VERSION ""

NS_ :

BS_:

BU_:

BU_: ExternalDevice EMUS_BMS
BU_: INV U2C VCU BMS

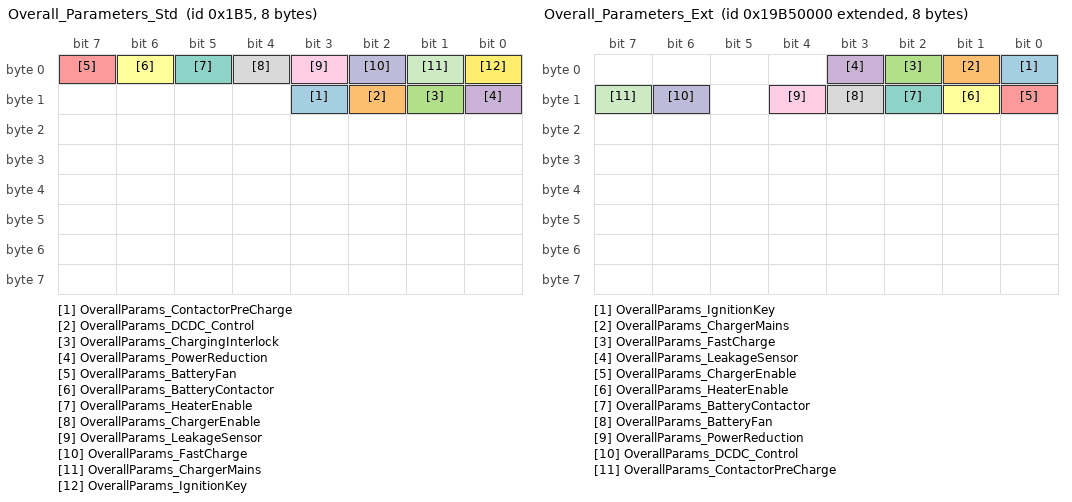
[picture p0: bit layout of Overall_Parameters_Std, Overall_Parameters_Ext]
BO_ 437 Overall_Parameters_Std: 8 EMUS_BMS
 SG_ OverallParams_ContactorPreCharge : 11|1@1+ (1,0) [0|1] "" Vector__XXX
 SG_ OverallParams_DCDC_Control : 10|1@1+ (1,0) [0|1] "" Vector__XXX
 SG_ OverallParams_ChargingInterlock : 9|1@1+ (1,0) [0|1] "" Vector__XXX
 SG_ OverallParams_PowerReduction : 8|1@1+ (1,0) [0|1] "" Vector__XXX
 SG_ OverallParams_BatteryFan : 7|1@1+ (1,0) [0|1] "" Vector__XXX
 SG_ OverallParams_BatteryContactor : 6|1@1+ (1,0) [0|1] "" Vector__XXX
 SG_ OverallParams_HeaterEnable : 5|1@1+ (1,0) [0|1] "" Vector__XXX
 SG_ OverallParams_ChargerEnable : 4|1@1+ (1,0) [0|1] "" Vector__XXX
 SG_ OverallParams_LeakageSensor : 3|1@1+ (1,0) [0|1] "" Vector__XXX
 SG_ OverallParams_FastCharge : 2|1@1+ (1,0) [0|1] "" Vector__XXX
 SG_ OverallParams_ChargerMains : 1|1@1+ (1,0) [0|1] "" Vector__XXX
 SG_ OverallParams_IgnitionKey : 0|1@1+ (1,0) [0|1] "" Vector__XXX

BO_ 2578776064 Overall_Parameters_Ext: 8 EMUS_BMS
 SG_ OverallParams_IgnitionKey : 0|1@1+ (1,0) [0|1] "" Vector__XXX
 SG_ OverallParams_ChargerMains : 1|1@1+ (1,0) [0|1] "" Vector__XXX
 SG_ OverallParams_FastCharge : 2|1@1+ (1,0) [0|1] "" Vector__XXX
 SG_ OverallParams_LeakageSensor : 3|1@1+ (1,0) [0|1] "" Vector__XXX
 SG_ OverallParams_ChargerEnable : 8|1@1+ (1,0) [0|1] "" Vector__XXX
 SG_ OverallParams_HeaterEnable : 9|1@1+ (1,0) [0|1] "" Vector__XXX
 SG_ OverallParams_BatteryContactor : 10|1@1+ (1,0) [0|1] "" Vector__XXX
 SG_ OverallParams_BatteryFan : 11|1@1+ (1,0) [0|1] "" Vector__XXX
 SG_ OverallParams_PowerReduction : 12|1@1+ (1,0) [0|1] "" Vector__XXX
 SG_ OverallParams_DCDC_Control : 14|1@1+ (1,0) [0|1] "" Vector__XXX
 SG_ OverallParams_ContactorPreCharge : 15|1@1+ (1,0) [0|1] "" Vector__XXX

BO_ 2578776071 Diagnostic_Codes_Ext: 8 EMUS_BMS
 SG_ DiagnosticCodes_UnderVoltage : 0|1@1+ (1,0) [0|1] "" Vector__XXX
 SG_ DiagnosticCodes_OverVoltage : 1|1@1+ (1,0) [0|1] "" Vector__XXX
 SG_ DiagnosticCodes_DchrgOvrCurrent : 2|1@1+ (1,0) [0|1] "" Vector__XXX
 SG_ DiagnosticCodes_ChrgOverCurrent : 3|1@1+ (1,0) [0|1] "" Vector__XXX
 SG_ DiagnosticCodes_CellModOverHeat : 4|1@1+ (1,0) [0|1] "" Vector__XXX
 SG_ DiagnosticCodes_Leakage : 5|1@1+ (1,0) [0|1] "" Vector__XXX
 SG_ DiagnosticCodes_NoCellComm : 6|1@1+ (1,0) [0|1] "" Vector__XXX
 SG_ DiagnosticCodes_LowVoltage : 8|1@1+ (1,0) [0|1] "" Vector__XXX
 SG_ DiagnosticCodes_HighCurrent : 9|1@1+ (1,0) [0|1] "" Vector__XXX
 SG_ DiagnosticCodes_HighCellModTemp : 10|1@1+ (1,0) [0|1] "" Vector__XXX
 SG_ DiagnosticCodes_CellOverHeat : 19|1@1+ (1,0) [0|1] "" Vector__XXX
 SG_ DiagnosticCodes_NoCurrentSensor : 20|1@1+ (1,0) [0|1] "" Vector__XXX
 SG_ DiagnosticCodes_PackUnderVoltage : 21|1@1+ (1,0) [0|1] "" Vector__XXX
 SG_ DiagnosticCodes_CellVoltValidity : 24|1@1+ (1,0) [0|1] "" Vector__XXX
 SG_ DiagnosticCodes_CellModTempValid : 25|1@1+ (1,0) [0|1] "" Vector__XXX
 SG_ DiagnosticCodes_CellBalancValid : 26|1@1+ (1,0) [0|1] "" Vector__XXX
 SG_ DiagnosticCodes_NumOfCellsValid : 27|1@1+ (1,0) [0|1] "" Vector__XXX
 SG_ DiagnosticCodes_BatChrgFinished : 28|1@1+ (1,0) [0|1] "" Vector__XXX
 SG_ DiagnosticCodes_CellTempValid : 29|1@1+ (1,0) [0|1] "" Vector__XXX
 SG_ DiagnosticCodes_MS_ConfError : 7|1@1+ (1,0) [0|1] "" Vector__XXX
 SG_ DiagnosticCodes_MSConfigMismatch : 11|1@1+ (1,0) [0|1] "" Vector__XXX
 SG_ DiagnosticCodes_MSComMalfunc : 12|1@1+ (1,0) [0|1] "" Vector__XXX
 SG_ DiagnosticCodes_HighCellTemp : 13|1@1+ (1,0) [0|1] "" Vector__XXX
 SG_ DiagnosticCodes_MSIntCANError : 16|1@1+ (1,0) [0|1] "" Vector__XXX
 SG_ DiagnosticCodes_MSCommCANFail : 17|1@1+ (1,0) [0|1] "" Vector__XXX
 SG_ DiagnosticCodes_ACPresnce : 18|1@1+ (1,0) [0|1] "" Vector__XXX

BO_ 444 Diagnostic_Codes_Std: 8 EMUS_BMS
 SG_ DiagnosticCodes_CellTempValid : 29|1@1+ (1,0) [0|1] "" Vector__XXX
 SG_ DiagnosticCodes_BatChrgFinished : 28|1@1+ (1,0) [0|1] "" Vector__XXX
 SG_ DiagnosticCodes_NumOfCellsValid : 27|1@1+ (1,0) [0|1] "" Vector__XXX
 SG_ DiagnosticCodes_CellBalancValid : 26|1@1+ (1,0) [0|1] "" Vector__XXX
 SG_ DiagnosticCodes_CellModTempValid : 25|1@1+ (1,0) [0|1] "" Vector__XXX
 SG_ DiagnosticCodes_CellVoltValidity : 24|1@1+ (1,0) [0|1] "" Vector__XXX
 SG_ DiagnosticCodes_PackUnderVoltage : 21|1@1+ (1,0) [0|1] "" Vector__XXX
 SG_ DiagnosticCodes_NoCurrentSensor : 20|1@1+ (1,0) [0|1] "" Vector__XXX
 SG_ DiagnosticCodes_CellOverHeat : 19|1@1+ (1,0) [0|1] "" Vector__XXX
 SG_ DiagnosticCodes_ACPresnce : 18|1@1+ (1,0) [0|1] "" Vector__XXX
 SG_ DiagnosticCodes_MSCommCANFail : 17|1@1+ (1,0) [0|1] "" Vector__XXX
 SG_ DiagnosticCodes_MSIntCANError : 16|1@1+ (1,0) [0|1] "" Vector__XXX
 SG_ DiagnosticCodes_HighCellTemp : 13|1@1+ (1,0) [0|1] "" Vector__XXX
 SG_ DiagnosticCodes_MSComMalfunc : 12|1@1+ (1,0) [0|1] "" Vector__XXX
 SG_ DiagnosticCodes_MSConfigMismatch : 11|1@1+ (1,0) [0|1] "" Vector__XXX
 SG_ DiagnosticCodes_HighCellModTemp : 10|1@1+ (1,0) [0|1] "" Vector__XXX
 SG_ DiagnosticCodes_HighCurrent : 9|1@1+ (1,0) [0|1] "" Vector__XXX
 SG_ DiagnosticCodes_LowVoltage : 8|1@1+ (1,0) [0|1] "" Vector__XXX
 SG_ DiagnosticCodes_MS_ConfError : 7|1@1+ (1,0) [0|1] "" Vector__XXX
 SG_ DiagnosticCodes_NoCellComm : 6|1@1+ (1,0) [0|1] "" Vector__XXX
 SG_ DiagnosticCodes_Leakage : 5|1@1+ (1,0) [0|1] "" Vector__XXX
 SG_ DiagnosticCodes_CellModOverHeat : 4|1@1+ (1,0) [0|1] "" Vector__XXX
 SG_ DiagnosticCodes_ChrgOverCurrent : 3|1@1+ (1,0) [0|1] "" Vector__XXX
 SG_ DiagnosticCodes_DchrgOvrCurrent : 2|1@1+ (1,0) [0|1] "" Vector__XXX
 SG_ DiagnosticCodes_OverVoltage : 1|1@1+ (1,0) [0|1] "" Vector__XXX
 SG_ DiagnosticCodes_UnderVoltage : 0|1@1+ (1,0) [0|1] "" Vector__XXX

BO_ 171 BMS_POST_Faults: 8 Vector__XXX
	SG_ Hardware_Gate_Desaturation_Fault : 0|1@1+ (1,0) [0|1] "" Vector__XXX
	SG_ HW_Over_current_Fault : 1|1@1+ (1,0) [0|1] "" Vector__XXX
	SG_ Accelerator_Shorted : 2|1@1+ (1,0) [0|1] "" Vector__XXX
	SG_ Accelerator_Open : 3|1@1+ (1,0) [0|1] "" Vector__XXX
	SG_ Current_Sensor_Low : 4|1@1+ (1,0) [0|1] "" Vector__XXX
	SG_ Current_Sensor_High : 5|1@1+ (1,0) [0|1] "" Vector__XXX
	SG_ Module_Temperature_Low : 6|1@1+ (1,0) [0|1] "" Vector__XXX
	SG_ Module_Temperature_High : 7|1@1+ (1,0) [0|1] "" Vector__XXX
	SG_ Control_PCB_Temperature_Low : 8|1@1+ (1,0) [0|1] "" Vector__XXX
	SG_ Control_PCB_Temperature_High : 9|1@1+ (1,0) [0|1] "" Vector__XXX
	SG_ Gate_Drive_PCB_Temperature_Low : 10|1@1+ (1,0) [0|1] "" Vector__XXX
	SG_ Gate_Drive_PCB_Temperature_High : 11|1@1+ (1,0) [0|1] "" Vector__XXX
	SG_ _5V_Sense_Voltage_Low : 12|1@1+ (1,0) [0|1] "" Vector__XXX
	SG_ _5V_Sense_Voltage_High : 13|1@1+ (1,0) [0|1] "" Vector__XXX
	SG_ _12V_Sense_Voltage_Low : 14|1@1+ (1,0) [0|1] "" Vector__XXX
	SG_ _12V_Sense_Voltage_High : 15|1@1+ (1,0) [0|1] "" Vector__XXX
	SG_ _2pt5V_Sense_Voltage_Low : 16|1@1+ (1,0) [0|1] "" Vector__XXX
	SG_ _2pt5V_Sense_Voltage_High : 17|1@1+ (1,0) [0|1] "" Vector__XXX
	SG_ _1pt5V_Sense_Voltage_Low : 18|1@1+ (1,0) [0|1] "" Vector__XXX
	SG_ _1pt5V_Sense_Voltage_High : 19|1@1+ (1,0) [0|1] "" Vector__XXX
	SG_ DC_Bust_Voltage_High : 20|1@1+ (1,0) [0|1] "" Vector__XXX
	SG_ DC_Bus_Voltage_Low : 21|1@1+ (1,0) [0|1] "" Vector__XXX
	SG_ Pre_charge_Timeout : 22|1@1+ (1,0) [0|1] "" Vector__XXX
	SG_ Pre_charge_Voltage_Failure : 23|1@1+ (1,0) [0|1] "" Vector__XXX
	SG_ EEPROM_Checksum_Invalid : 24|1@1+ (1,0) [0|1] "" Vector__XXX
	SG_ EEPROM_Date_Out_of_Range : 25|1@1+ (1,0) [0|1] "" Vector__XXX
	SG_ EEPROM_Update_Required : 26|1@1+ (1,0) [0|1] "" Vector__XXX
	SG_ Hardware_DC_Bus_Over_Voltage_dur : 27|1@1+ (1,0) [0|1] "" Vector__XXX
	SG_ Gate_Driver_Initialization : 28|1@1+ (1,0) [0|1] "" Vector__XXX
	SG_ Reserved : 29|1@1+ (1,0) [0|1] "" Vector__XXX
	SG_ Brake_Shorten : 30|1@1+ (1,0) [0|1] "" Vector__XXX
	SG_ Brake_Open : 31|1@1+ (1,0) [0|1] "" Vector__XXX
	SG_ Motor_Over_speed_Fault : 32|1@1+ (1,0) [0|1] "" Vector__XXX
	SG_ Over_current_Fault : 33|1@1+ (1,0) [0|1] "" Vector__XXX
	SG_ Inverter_Over_temperature_Fault : 34|1@1+ (1,0) [0|1] "" Vector__XXX
	SG_ Accelerator_Input_Shorted_Fault : 35|1@1+ (1,0) [0|1] "" Vector__XXX
	SG_ Accelerator_Input_Open_Fault : 36|1@1+ (1,0) [0|1] "" Vector__XXX
	SG_ Direction_Command_Fault : 37|1@1+ (1,0) [0|1] "" Vector__XXX
	SG_ Inverter_Response_Time_out_Fault : 38|1@1+ (1,0) [0|1] "" Vector__XXX
	SG_ Hardware_Gate_Desaturation_2 : 39|1@1+ (1,0) [0|1] "" Vector__XXX
	SG_ Hardware_Over_current_Fault : 40|1@1+ (1,0) [0|1] "" Vector__XXX
	SG_ Under_voltage_Fault : 41|1@1+ (1,0) [0|1] "" Vector__XXX
	SG_ CAN_Command_Message_Lost_Fault : 42|1@1+ (1,0) [0|1] "" Vector__XXX
	SG_ Motor_Over_temperature_Fault : 43|1@1+ (1,0) [0|1] "" Vector__XXX
	SG_ Brake_Input_Shorted_Fault : 47|1@1+ (1,0) [0|1] "" Vector__XXX
	SG_ Brake_Input_Open_Fault : 48|1@1+ (1,0) [0|1] "" Vector__XXX
	SG_ Module_A_Over_temperature_Fault : 49|1@1+ (1,0) [0|1] "" Vector__XXX
	SG_ Module_B_Over_temperature_Fault : 50|1@1+ (1,0) [0|1] "" Vector__XXX
	SG_ Module_C_Over_temperature_Fault : 51|1@1+ (1,0) [0|1] "" Vector__XXX
	SG_ PCB_Over_temperature_Fault : 52|1@1+ (1,0) [0|1] "" Vector__XXX
	SG_ Gate_Drive_Board_1_Over_temp_Flt : 53|1@1+ (1,0) [0|1] "" Vector__XXX
	SG_ Gate_Drive_Board_2_Over_temp_Flt : 54|1@1+ (1,0) [0|1] "" Vector__XXX
	SG_ Gate_Drive_Board_3_Over_temp_Flt : 55|1@1+ (1,0) [0|1] "" Vector__XXX
	SG_ Current_Sensor_Fault : 56|1@1+ (1,0) [0|1] "" Vector__XXX
	SG_ Gate_Driver_Over_Voltage : 57|1@1+ (1,0) [0|1] "" Vector__XXX
	SG_ Hardware_DC_Bus_Over_voltage_Flt : 60|1@1+ (1,0) [0|1] "" Vector__XXX
	SG_ Resolver_Not_Connected : 62|1@1+ (1,0) [0|1] "" Vector__XXX

CM_ SG_ 2147483819 Hardware_Gate_Desaturation_Fault "Wheel-Based Vehicle Speed: Speed of the vehicle as calculated from wheel or tailshaft speed.";
BA_DEF_ SG_  "SPN" INT 0 524287;
BA_DEF_ BO_  "VFrameFormat" ENUM  "StandardCAN","ExtendedCAN","reserved","J1939PG";
BA_DEF_  "DatabaseVersion" STRING ;
BA_DEF_  "BusType" STRING ;
BA_DEF_  "ProtocolType" STRING ;
BA_DEF_  "DatabaseCompiler" STRING ;
BA_DEF_DEF_  "SPN" 0;
BA_DEF_DEF_  "VFrameFormat" "J1939PG";
BA_DEF_DEF_  "DatabaseVersion" "DEMO PLUS";
BA_DEF_DEF_  "BusType" "";
BA_DEF_DEF_  "ProtocolType" "";
BA_DEF_DEF_  "DatabaseCompiler" "";
BA_ "ProtocolType" "J1939";
BA_ "DatabaseCompiler" "CSS ELECTRONICS (WWW.CSSELECTRONICS.COM)";
BA_ "DatabaseVersion" "1.0.0";
BA_ "SPN" SG_ 2566844926 WheelBasedVehicleSpeed 84;

CM_ BU_ INV "The Cascadia Motion inverter";
CM_ BU_ U2C "Delphi DC/DC Converter";
CM_ BU_ VCU "The system vehicle control unit";
CM_ BU_ BMS "BMS Master";
CM_ SG_ 173 D4_Iq_Command "The commanded Q-axis current";
CM_ SG_ 173 D3_Id_Command "The commanded D-axis current";
CM_ SG_ 173 D2_Flux_Weakening_Output "This is the current output of the flux regulator.";
CM_ SG_ 173 D1_Modulation_Index "This is the modulation index. The scale factor is x100. To get the actual modulation index divide the value by 100.";
CM_ SG_ 172 D3_Power_On_Timer "Updated every 3 msec. This will roll over in approximately 150 days!";
CM_ SG_ 172 D2_Torque_Feedback "Estimated motor torque feedback";
CM_ SG_ 172 D1_Commanded_Torque "The commanded Torque";
CM_ BO_ 194 "The inverter response to each Parameter message that is received.";
CM_ SG_ 194 D2_Write_Success "0=Write failure, 1=Success";
CM_ SG_ 194 D3_Data_Response "All EEPROM data is 16 bits and is contained in bytes 4 and 5. Bytes 6 and 7 should be ignored.";
CM_ SG_ 194 D1_Parameter_Address_Response "Valid EEPROM Parameter CAN addresses are between 100 and 499.";
CM_ BO_ 193 "Parameter Message sent as needed by VCU to request info, change EEPROM, or command a function.";
CM_ SG_ 193 D3_Data_Command "All EEPROM data is 16 bits and is contained in bytes 4 and 5.";
CM_ SG_ 193 D2_Read_Write_Command "0=Read, 1=Write";
CM_ SG_ 193 D1_Parameter_Address_Command "Valid EEPROM Parameter CAN addresses are between 100 and 499.";
CM_ BO_ 192 "The command message is used to transmit data to the controller. This message is sent from a user supplied external controller to the PMxxx controller.";
CM_ SG_ 192 Inverter_Enable "0=Inverter OFF, 1 = Inverter ON";
CM_ SG_ 192 Direction_Command "0=CW, 1=CCW as veiwed from the shaft end of the motor";
CM_ SG_ 192 Speed_Command "Speed commandused when in speed mode";
CM_ SG_ 192 Torque_Command "Torque command when in torque mode";
CM_ SG_ 192 Inverter_Discharge "0=Discharge Disable,
=Discharge Enable";
CM_ SG_ 192 Torque_Limit_Command "Torque Limit, set to 0 to keep default";
CM_ SG_ 192 Speed_Mode_Enable "0 = No change to mode, 1 = change to speed mode from torque mode";
CM_ SG_ 192 RollingCounter "Rolling Counter command";
CM_ SG_ 171 D4_Run_Fault_Hi "Each bit represents a fault. Please refer to PM100 Users Manual for details.";
CM_ SG_ 171 D2_Post_Fault_Hi "Each bit represents a fault. Please refer to PM100 Users Manual for details.";
CM_ SG_ 171 D3_Run_Fault_Lo "Each bit represents a fault. Please refer to PM100 Users Manual for details.";
CM_ SG_ 171 D1_Post_Fault_Lo "Each bit represents a fault. Please refer to PM100 Users Manual for details.";
CM_ SG_ 170 D7_Direction_Command "1 = Forward
0 = 'Reverse' if inverter enabled  & 'Stopped' if inverter is disabled";
CM_ SG_ 170 D6_Inverter_Enable_State "0=Inverter Disabled, 
1=Inverter Enabled";
CM_ SG_ 170 D3_Relay_3_Status "0=OFF, 1=ON";
CM_ SG_ 170 D3_Relay_4_Status "0=OFF, 1=ON";
CM_ SG_ 170 D3_Relay_2_Status "0=OFF, 1=ON";
CM_ SG_ 170 D4_Inverter_Run_Mode "0=Torque Mode, 1=Speed Mode";
CM_ SG_ 170 D5_Inverter_Command_Mode "0=CAN mode, 1=VSM mode";
CM_ SG_ 170 D3_Relay_1_Status "0=OFF, 1=ON";
CM_ SG_ 170 D2_Inverter_State "Different states for the inverter state machine";
CM_ SG_ 170 D1_VSM_State "Different states for the vehicle state machine";
CM_ SG_ 170 D6_Inverter_Enable_Lockout "0=Lockout Disabled, 1=Lockout Enabled";
CM_ SG_ 170 D4_Inverter_Discharge_State "0 = Disabled, 1 = Enabled, 2 = Speed Check, 3 = Active, 4 = Complete";
CM_ SG_ 170 D3_Relay_5_Status "0=OFF, 1=ON";
CM_ SG_ 170 D3_Relay_6_Status "0=OFF, 1=ON";
CM_ SG_ 170 D7_BMS_Active "0 = BMS Not Active, 1 = BMS Active";
CM_ SG_ 170 D7_BMS_Torque_Limiting "0 = Not Limiting, 1 = Limiting";
CM_ SG_ 170 D7_Max_Speed_Limiting "0 = Not Limiting, 1 = torque limiting due to maximum speed";
CM_ SG_ 170 D7_Low_Speed_Limiting "0 = Not Limiting, 1 = Current limiting due to low motor speed";
CM_ SG_ 170 D5_Rolling_Counter "The current rolling counter value.";
CM_ SG_ 170 D1_PWM_Frequency "The inverter PWM frequency";
CM_ SG_ 170 D6_Start_Mode_Active "If in Key Switch Mode 1 then indicates status of Start input being applied.  0 = not active, 1 = active";
CM_ SG_ 169 D4_Reference_Voltage_12_0 "12V Input Voltage";
CM_ SG_ 169 D3_Reference_Voltage_5_0 "Transducer voltage";
CM_ SG_ 169 D2_Reference_Voltage_2_5 "Internal reference voltage";
CM_ SG_ 169 D1_Reference_Voltage_1_5 "Internal reference voltage";
CM_ SG_ 168 D4_Iq "The measured Iq current";
CM_ SG_ 168 D3_Id "The measured Id current";
CM_ SG_ 168 D2_Flux_Feedback "The estimated flux";
CM_ SG_ 168 D1_Flux_Command "The commanded flux";
CM_ SG_ 167 D4_VBC_Vq_Voltage "Measured value of the voltage between Phase B and Phase C";
CM_ SG_ 167 D3_VAB_Vd_Voltage "Measured value of the voltage betwen phase A and Phase B";
CM_ SG_ 167 D2_Output_Voltage "The calculated value of the output voltage, in peak line-neutral volts";
CM_ SG_ 167 D1_DC_Bus_Voltage "The actual measured value of the DC bus voltage";
CM_ SG_ 166 D4_DC_Bus_Current "The Calculated DC Bus Current";
CM_ SG_ 166 D3_Phase_C_Current "The measured value of Phase C current";
CM_ SG_ 166 D2_Phase_B_Current "The measured value of Phase B current";
CM_ SG_ 166 D1_Phase_A_Current "The measured value of Phase A current";
CM_ SG_ 165 D4_Delta_Resolver_Filtered "Used in calibration of resolver angle adjustment.";
CM_ SG_ 165 D3_Electrical_Output_Frequency "The actual electrical frequency of the inverter";
CM_ SG_ 165 D2_Motor_Speed "The measured speed of the motor";
CM_ SG_ 165 D1_Motor_Angle_Electrical "The Electrical Angle of the motor as read by the encoder or resolver";
CM_ SG_ 164 D5_Digital_Input_5 "Status of Digital Input #5";
CM_ SG_ 164 D4_Digital_Input_4 "Status of Digital Input #4";
CM_ SG_ 164 D3_Digital_Input_3 "Status of Digital Input #3";
CM_ SG_ 164 D2_Digital_Input_2 "Status of Digital Input #2";
CM_ SG_ 164 D1_Digital_Input_1 "Status of Digital Input #1";
CM_ SG_ 164 D6_Digital_Input_6 "Status of Digital Input #6";
CM_ SG_ 164 D7_Digital_Input_7 "Status of Digital Input #7";
CM_ SG_ 164 D8_Digital_Input_8 "Status of Digital Input #8";
CM_ SG_ 163 D4_Analog_Input_4 "Voltage on Analog Input #4";
CM_ SG_ 163 D3_Analog_Input_3 "Voltage on Analog Input #3";
CM_ SG_ 163 D2_Analog_Input_2 "Voltage on Analog Input #2";
CM_ SG_ 163 D1_Analog_Input_1 "Voltage on Analog Input #1";
CM_ SG_ 163 D5_Analog_Input_5 "Voltage on Analog Input #5";
CM_ SG_ 163 D6_Analog_Input_6 "Voltage on Analog Input #6";
CM_ SG_ 162 D4_Torque_Shudder "Shudder compensation value of torque";
CM_ SG_ 162 D3_Motor_Temperature "Motor Temperature Sensor";
CM_ SG_ 162 D2_RTD5_Temperature "RTD 5 (PT1000) Temperature (Gen 2 only)";
CM_ SG_ 162 D1_RTD4_Temperature "RTD 4 (PT1000) Temperature (Gen 2 only)";
CM_ SG_ 161 D4_RTD3_Temperature "RTD input 3 (PT1000) Temperature (Gen 2 only)";
CM_ SG_ 161 D3_RTD2_Temperature "RTD input 2 (PT1000) Temperature";
CM_ SG_ 161 D2_RTD1_Temperature "RTD input 1 (PT1000) Temperature";
CM_ SG_ 161 D1_Control_Board_Temperature "Control Board Temperature";
CM_ SG_ 160 D4_Gate_Driver_Board "Gate Driver Board Temperature";
CM_ SG_ 160 D3_Module_C "IGBT Module C Temperature";
CM_ SG_ 160 D2_Module_B "IGBT Module B Temperature";
CM_ SG_ 160 D1_Module_A "IGBT Module A Temperature";
CM_ BO_ 471 "Enable message sent to Delphi DC/DC converter.";
CM_ BO_ 469 "Response from Delphi DC/DC converter.";
CM_ BO_ 514 "Message sent by BMS for inverter DC current limiting.";
CM_ SG_ 514 D1_Max_Discharge_Current "Maximum discharge current from BMS";
CM_ SG_ 514 D2_Max_Charge_Current "Maximum charge current from BMS";
CM_ BO_ 176 "To enable fast message set CAN ACTIVE MSGS HI WORD to 0xFFFE.  Setting to default value of 0xFFFF will disable the fast message.";
CM_ SG_ 176 Fast_Torque_Command "The commanded torque";
CM_ SG_ 176 Fast_Torque_Feedback "The estimated torque";
CM_ SG_ 176 Fast_Motor_Speed "Motor speed";
CM_ SG_ 176 Fast_DC_Bus_Voltage "DC Bus Voltage";
BA_DEF_ BO_  "GenMsgCycleTime" INT 0 100000;
BA_DEF_  "BusType" STRING ;
BA_DEF_DEF_  "GenMsgCycleTime" 0;
BA_DEF_DEF_  "BusType" "CAN";
BA_ "GenMsgCycleTime" BO_ 172 10;
BA_ "GenMsgCycleTime" BO_ 192 5;
BA_ "GenMsgCycleTime" BO_ 171 100;
BA_ "GenMsgCycleTime" BO_ 170 100;
BA_ "GenMsgCycleTime" BO_ 169 100;
BA_ "GenMsgCycleTime" BO_ 168 10;
BA_ "GenMsgCycleTime" BO_ 167 10;
BA_ "GenMsgCycleTime" BO_ 166 10;
BA_ "GenMsgCycleTime" BO_ 165 10;
BA_ "GenMsgCycleTime" BO_ 164 10;
BA_ "GenMsgCycleTime" BO_ 163 10;
BA_ "GenMsgCycleTime" BO_ 162 100;
BA_ "GenMsgCycleTime" BO_ 161 100;
BA_ "GenMsgCycleTime" BO_ 160 100;
BA_ "GenMsgCycleTime" BO_ 176 3;
VAL_ 192 Inverter_Enable 0 "Turn the inverter OFF" 1 "Turn the Inverter ON" ;
VAL_ 192 Direction_Command 0 "CW" 1 "CCW" ;
VAL_ 192 Inverter_Discharge 0 "Discharge Disable" 1 "Discharge Enable (if EEPROM parameter is set)" ;
VAL_ 170 D2_Inverter_State 0 "Power up" 1 "Stop" 2 "Open Loop" 3 "Closed Loop" 4 "Internal State" 5 "Internal State" 6 "Internal State" 7 "Internal State" 8 "Idle Run" 9 "Idle Stop" 10 "Internal State" 11 "Intern State" 12 "Internal State" ;
VAL_ 170 D1_VSM_State 0 "VSM Start State" 1 "Pre-Charge Init state" 2 "pre-charge active state" 3 "pre-charge complete state" 4 "VSM wait state" 5 "VSM ready state" 6 "Motor Running State" 7 "blink fault code state" 14 "Shutdown state for Key Switch Mode 1" 15 "Reset the inverter" ;

CM_ BO_ 2578776070 "Energy Parameters Extended";
CM_ BO_ 2578776069 "State Of Charge Parameters Extended";
CM_ BO_ 2578776065 "Battery Voltage Overall Parameters Extended";
CM_ BO_ 2578776064 "Overall Parameters Extended";
CM_ BO_ 2578776071 "Diagnostic Codes Extended";
CM_ SG_ 2578776071 DiagnosticCodes_MSComMalfunc "DiagnosticCodes Master Slave Communication Malfunction";
CM_ BO_ 2578776066 "Cell Module Temperature Overall Parameters Extended";
CM_ BO_ 2578776072 "Cell Temperature Overall Parameters Extended";
CM_ BO_ 2578776067 "Cell Balancing Overall Parameters Extended";
CM_ BO_ 2578777088 "Configuration Parameters Extended";
CM_ BO_ 2578777090 "Login Request Response Extended";
CM_ BO_ 2578777089 "Contactor Control Extended";
CM_ BO_ 2578777600 "Energy Parameters Extended";
CM_ BO_ 2578777344 "State Of Charge Parameters Extended";
CM_ BO_ 2578777092 "Statistics Extended";
CM_ BO_ 2578777093 "Events Extended";
CM_ BO_ 2578776320 "Individual Cells Voltages Extended Option A";
CM_ BO_ 2578776576 "Individual Cell Module Temperatures Extended Option A";
CM_ BO_ 2578778112 "Individual Cell Temperatures Extended Option A";
CM_ BO_ 450 "Individual Cell Balancing Rates Standard Option B";
CM_ SG_ 450 Individual_Cells_Group_Opt_B "Individual Cells Group Value for CAN Option B";
CM_ BO_ 437 "Overall Parameters Standard";
CM_ BO_ 444 "Diagnostic Codes Standard";
CM_ SG_ 444 DiagnosticCodes_MSComMalfunc "DiagnosticCodes Master Slave Communication Malfunction";
CM_ BO_ 438 "Battery Voltage Overall Parameters Standard";
CM_ BO_ 439 "Cell Module Overall Parameters Standard";
CM_ BO_ 445 "Cell Temperature Overall Params Standard";
CM_ BO_ 440 "Cell Bancing Rate Overall Params Standard";
CM_ BO_ 469 "Individual Cells Voltages Standard Option A";
CM_ BO_ 501 "Individual Cell Module Temperature Standard Option A";
CM_ BO_ 693 "Individual Cell Temperatures Standard Option A";
CM_ BO_ 533 "Individual Cell Balancing Rates Standard Option A";
CM_ BO_ 566 "Contactor Control Standard";
CM_ BO_ 443 "Energy Parameters Standard";
CM_ BO_ 442 "State Of Charge Parameters Standard";
CM_ BO_ 569 "Statistics Standard";
CM_ BO_ 2578776075 "Individual Cells Voltages Extended Option B";
CM_ SG_ 2578776075 Individual_Cells_Group_Opt_B "Individual Cells Group Value for CAN Option B";
CM_ BO_ 448 "Individual Cells Voltages Standard Option B";
CM_ SG_ 448 Individual_Cells_Group_Opt_B "Individual Cells Group Value for CAN Option B";
CM_ BO_ 2578776077 "Individual Cell Balancing Rate Extended Option B";
CM_ SG_ 2578776077 Individual_Cells_Group_Opt_B "Individual Cells Group Value for CAN Option B";
CM_ BO_ 2578776832 "Individual Cell Balancing Rate Extended Option A";
CM_ BO_ 2578776076 "Individual Cell Modules Temperature Extended Option B";
CM_ SG_ 2578776076 Individual_Cells_Group_Opt_B "Individual Cells Group Value for CAN Option B";
CM_ BO_ 449 "Individual Cell Module Temperature Standard Option B";
CM_ SG_ 449 Individual_Cells_Group_Opt_B "Individual Cells Group Value for CAN Option B";
CM_ BO_ 2578776078 "Individual Cell Temperatures Extended Option B";
CM_ SG_ 2578776078 Individual_Cells_Group_Opt_B "Individual Cells Group Value for CAN Option B";
CM_ BO_ 451 "Individual Cell Temperature Standard Option B";
CM_ SG_ 451 Individual_Cells_Group_Opt_B "Individual Cells Group Value for CAN Option B";
CM_ SG_ 1328 Neuro4_FirstByteFirstBit "Contactor State";
CM_ SG_ 1328 Neuro4_FirstByteSecondBit "if max cell voltage is less than fully charge minus balancing range, then allow regeneration";
BA_DEF_  "BusType" STRING ;
BA_DEF_DEF_  "BusType" "CAN";
VAL_ 2578776064 OverallParams_IgnitionKey 0 "OFF" 1 "ON" ;
VAL_ 2578776064 OverallParams_ChargerMains 0 "OFF" 1 "ON" ;
VAL_ 2578776064 OverallParams_FastCharge 0 "OFF" 1 "ON" ;
VAL_ 2578776064 OverallParams_LeakageSensor 0 "OFF" 1 "ON" ;
VAL_ 2578776064 OverallParams_ChargerEnable 0 "OFF" 1 "ON" ;
VAL_ 2578776064 OverallParams_HeaterEnable 0 "OFF" 1 "ON" ;
VAL_ 2578776064 OverallParams_BatteryContactor 0 "OFF" 1 "ON" ;
VAL_ 2578776064 OverallParams_BatteryFan 0 "OFF" 1 "ON" ;
VAL_ 2578776064 OverallParams_PowerReduction 0 "OFF" 1 "ON" ;
VAL_ 2578776064 OverallParams_DCDC_Control 0 "OFF" 1 "ON" ;
VAL_ 2578776064 OverallParams_ContactorPreCharge 0 "OFF" 1 "ON" ;
VAL_ 2578776064 OverallParams_ChargingStage 0 "OFF" 1 "ON" ;
VAL_ 2578776064 OverallParams_LastChargingError 0 "No Error" 1 "No Cell Communication" 2 "No Cell Communication 2" 3 "Maximum Charging Stage Duration Expired" 4 "Cell Communication Lost" 5 "Cannot Set Cell Module Balancing Threshold" 6 "Cell or Cell Module Temperature To High" 7 "Cell Commucation Lost 2" 8 "Number Of Cells Mismatch" 9 "Cell Over Voltage" 10 "Cell Protection Event Occurred" ;
VAL_ 2578776064 OverallParams_ChargingInterlock 0 "OFF" 1 "ON" ;
VAL_ 2578776064 OverallParams_ChrgStageDurat_LSB 0 "No Error" 1 "No Cell Communication" 2 "No Cell Communication 2" 3 "Maximum Charging Stage Duration Expired" 4 "Cell Communication Lost" 5 "Cannot Set Cell Module Balancing Threshold" 6 "Cell or Cell Module Temperature To High" 7 "Cell Commucation Lost 2" 8 "Number Of Cells Mismatch" 9 "Cell Over Voltage" 10 "Cell Protection Event Occurred" ;
VAL_ 2578777090 LoginLevel 0 "Guest" 1 "User" 2 "Admin" ;
VAL_ 2578777089 ContactorControl_ContactorState 0 "OPEN" 1 "CLOSE" ;
VAL_ 2578777092 Statistics_Identifier 0 "Total Disharge" 1 "Total Charge" 2 "Total Discharge Energy" 3 "Total Charge Energy" 4 "Total Discharge Time" 5 "Total Charge Time" 6 "Total Distance" 7 "Master Clear Count" 8 "Max Discharge Current" 9 "Max Charge Current" 10 "Min Cell Voltage" 11 "Max Cell Voltage" 12 "Max Cell Voltage Difference" 13 "Min Pack Voltage" 14 "Max Pack Voltage" 15 "Min Cell Module Temperature" 16 "Max Cell Module Temperature" 17 "Max Cell Module Temperature Difference" 18 "BMS Starts Count" 19 "Under Voltage Protection Count" 20 "Over Voltage Protection Count" 21 "Discharge Over Current Protection Count" 22 "Charge Over Current Protection Count" 23 "Cell Module Over Heat Protection Count" 24 "Leakage Protection Count" 25 "No Cell Communication Protection Count" 26 "Low Voltage Power Reduction Count" 27 "High Current Power Reduction Count" 28 "High Cell Module Temp Power Reduction Count" 29 "Charger Connected Count" 30 "Charger Disconnected Count" 31 "Pre Heat Stage Count" 32 "Pre Charge Stage Count" 33 "Main Charge Stage Count" 34 "Balancing Stage Count" 35 "Charging Finished Count" 36 "Charging Error Count" 37 "Charging Retry Count" 38 "Trips Count" 39 "Charge Restarts Count" 40 "Cell Over Heat Protection Count" 41 "High Cell Temperature Power Reduction Count" 42 "Min Cell Temperature" 43 "Max Cell Temperature Count" 44 "Max Cell Temperature Difference" ;
VAL_ 2578777092 Statistics_DataType 0 "Statistics Value" 1 "Additional Value" 2 "Statistics Timestamp" ;
VAL_ 2578777093 Events_DataType 0 "Event Info " 1 "Event timestamp" ;
VAL_ 2578777093 Events_Data 0 "No event" 1 "BMS Started" 2 "Lost Communication To Cells" 3 "Established Communication To Cells" 4 "Cells Voltage Critically Low" 5 "Critical Low Voltage Recovered" 6 "Cells Voltage Critically High " 7 "Critical High Voltage Recovered" 8 "Discharge Current Critically High" 9 "Discharge Critically High Current Recovered" 10 "Charge Current Critically High" 11 "Charge Critically High Current Recovered" 12 "Cell Module Temperature Critically High" 13 "Critical High Cell Module Temperature Recovered" 14 "Leakage Detected" 15 "Leakage Recovered" 16 "Warning: Low Voltage - Reducing Power" 17 "Power Reduction Due To Low Voltage Recovered" 18 "Warning: High Current - Reducing Power" 19 "Power Reduction Due To High Current Recovered" 20 "Warning: High Cell Module Temperature - Reducing Power" 21 "Power Reduction Due To High Cell Module Temperature Recovered" 22 "Charger Connected" 23 "Charger Disconnected" 24 "Started Pre-Heating Stage" 25 "Started Pre-Charging Stage" 26 "Started Main-Charging Stage" 27 "Started Balancing Stage" 28 "Charging Finished" 29 "Charging Error Occured" 30 "Retrying Charging" 31 "Restarting Charging" 32 "Cell Temperature Critically High" 33 "Critically High Cell Temperature Recovered" 34 "Warning: High Cell Temperature - Reducing Power" 35 "Power Reduction Due To High Cell Temperature Recovered" ;
VAL_ 437 OverallParams_LastChargingError 0 "No Error" 1 "No Cell Communication" 2 "No Cell Communication 2" 3 "Maximum Charging Stage Duration Expired" 4 "Cell Communication Lost" 5 "Cannot Set Cell Module Balancing Threshold" 6 "Cell or Cell Module Temperature To High" 7 "Cell Commucation Lost 2" 8 "Number Of Cells Mismatch" 9 "Cell Over Voltage" 10 "Cell Protection Event Occurred" ;
VAL_ 437 OverallParams_ChrgStageDurat_LSB 0 "No Error" 1 "No Cell Communication" 2 "No Cell Communication 2" 3 "Maximum Charging Stage Duration Expired" 4 "Cell Communication Lost" 5 "Cannot Set Cell Module Balancing Threshold" 6 "Cell or Cell Module Temperature To High" 7 "Cell Commucation Lost 2" 8 "Number Of Cells Mismatch" 9 "Cell Over Voltage" 10 "Cell Protection Event Occurred" ;
VAL_ 437 OverallParams_ChargingStage 0 "OFF" 1 "ON" ;
VAL_ 437 OverallParams_ContactorPreCharge 0 "OFF" 1 "ON" ;
VAL_ 437 OverallParams_DCDC_Control 0 "OFF" 1 "ON" ;
VAL_ 437 OverallParams_ChargingInterlock 0 "OFF" 1 "ON" ;
VAL_ 437 OverallParams_PowerReduction 0 "OFF" 1 "ON" ;
VAL_ 437 OverallParams_BatteryFan 0 "OFF" 1 "ON" ;
VAL_ 437 OverallParams_BatteryContactor 0 "OFF" 1 "ON" ;
VAL_ 437 OverallParams_HeaterEnable 0 "OFF" 1 "ON" ;
VAL_ 437 OverallParams_ChargerEnable 0 "OFF" 1 "ON" ;
VAL_ 437 OverallParams_LeakageSensor 0 "OFF" 1 "ON" ;
VAL_ 437 OverallParams_FastCharge 0 "OFF" 1 "ON" ;
VAL_ 437 OverallParams_ChargerMains 0 "OFF" 1 "ON" ;
VAL_ 437 OverallParams_IgnitionKey 0 "OFF" 1 "ON" ;
VAL_ 566 ContactorControl_ContactorState 0 "OPEN" 1 "CLOSE" ;
VAL_ 570 Events_Data 0 "No event" 1 "BMS Started" 2 "Lost Communication To Cells" 3 "Established Communication To Cells" 4 "Cells Voltage Critically Low" 5 "Critical Low Voltage Recovered" 6 "Cells Voltage Critically High " 7 "Critical High Voltage Recovered" 8 "Discharge Current Critically High" 9 "Discharge Critically High Current Recovered" 10 "Charge Current Critically High" 11 "Charge Critically High Current Recovered" 12 "Cell Module Temperature Critically High" 13 "Critical High Cell Module Temperature Recovered" 14 "Leakage Detected" 15 "Leakage Recovered" 16 "Warning: Low Voltage - Reducing Power" 17 "Power Reduction Due To Low Voltage Recovered" 18 "Warning: High Current - Reducing Power" 19 "Power Reduction Due To High Current Recovered" 20 "Warning: High Cell Module Temperature - Reducing Power" 21 "Power Reduction Due To High Cell Module Temperature Recovered" 22 "Charger Connected" 23 "Charger Disconnected" 24 "Started Pre-Heating Stage" 25 "Started Pre-Charging Stage" 26 "Started Main-Charging Stage" 27 "Started Balancing Stage" 28 "Charging Finished" 29 "Charging Error Occured" 30 "Retrying Charging" 31 "Restarting Charging" 32 "Cell Temperature Critically High" 33 "Critically High Cell Temperature Recovered" 34 "Warning: High Cell Temperature - Reducing Power" 35 "Power Reduction Due To High Cell Temperature Recovered" ;
VAL_ 570 Events_DataType 0 "Event Info " 1 "Event timestamp" ;
VAL_ 567 LoginLevel 0 "Guest" 1 "User" 2 "Admin" ;
VAL_ 569 Statistics_DataType 0 "Statistics Value" 1 "Additional Value" 2 "Statistics Timestamp" ;
VAL_ 569 Statistics_Identifier 0 "Total Disharge" 1 "Total Charge" 2 "Total Discharge Energy" 3 "Total Charge Energy" 4 "Total Discharge Time" 5 "Total Charge Time" 6 "Total Distance" 7 "Master Clear Count" 8 "Max Discharge Current" 9 "Max Charge Current" 10 "Min Cell Voltage" 11 "Max Cell Voltage" 12 "Max Cell Voltage Difference" 13 "Min Pack Voltage" 14 "Max Pack Voltage" 15 "Min Cell Module Temperature" 16 "Max Cell Module Temperature" 17 "Max Cell Module Temperature Difference" 18 "BMS Starts Count" 19 "Under Voltage Protection Count" 20 "Over Voltage Protection Count" 21 "Discharge Over Current Protection Count" 22 "Charge Over Current Protection Count" 23 "Cell Module Over Heat Protection Count" 24 "Leakage Protection Count" 25 "No Cell Communication Protection Count" 26 "Low Voltage Power Reduction Count" 27 "High Current Power Reduction Count" 28 "High Cell Module Temp Power Reduction Count" 29 "Charger Connected Count" 30 "Charger Disconnected Count" 31 "Pre Heat Stage Count" 32 "Pre Charge Stage Count" 33 "Main Charge Stage Count" 34 "Balancing Stage Count" 35 "Charging Finished Count" 36 "Charging Error Count" 37 "Charging Retry Count" 38 "Trips Count" 39 "Charge Restarts Count" 40 "Cell Over Heat Protection Count" 41 "High Cell Temperature Power Reduction Count" 42 "Min Cell Temperature" 43 "Max Cell Temperature Count" 44 "Max Cell Temperature Difference" ;
VAL_ 1328 Neuro4_FirstByteFirstBit 0 "OPEN" 1 "CLOSE" ;
VAL_ 1328 Neuro4_ChargingStatus 0 "Not Charging" 1 "Charing In Progress" 2 "Charging Completed" 3 "Charging Fault" ;
